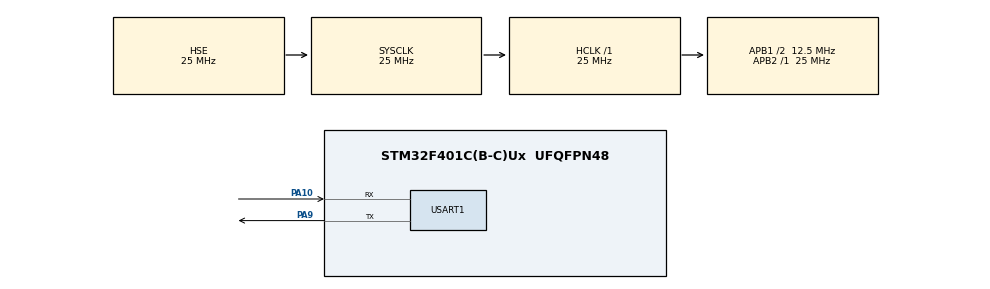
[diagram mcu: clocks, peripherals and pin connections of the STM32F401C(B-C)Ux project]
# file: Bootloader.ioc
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Mcu.Family=STM32F4
Mcu.Name=STM32F401C(B-C)Ux
Mcu.Package=UFQFPN48
NVIC.PriorityGroup=NVIC_PRIORITYGROUP_4
PA10.Mode=Asynchronous
PA10.Signal=USART1_RX
PA9.Mode=Asynchronous
PA9.Signal=USART1_TX
PH0\ -\ OSC_IN.Mode=HSE-External-Oscillator
PH0\ -\ OSC_IN.Signal=RCC_OSC_IN
PH1\ -\ OSC_OUT.Mode=HSE-External-Oscillator
PH1\ -\ OSC_OUT.Signal=RCC_OSC_OUT
ProjectManager.HeapSize=0x200
ProjectManager.StackSize=0x400
ProjectManager.TargetToolchain=STM32CubeIDE
RCC.48MHZClocksFreq_Value=26880000
RCC.AHBFreq_Value=25000000
RCC.APB1CLKDivider=RCC_HCLK_DIV2
RCC.APB1Freq_Value=12500000
RCC.APB1TimFreq_Value=25000000
RCC.APB2Freq_Value=25000000
RCC.APB2TimFreq_Value=25000000
RCC.CortexFreq_Value=25000000
RCC.HCLKFreq_Value=25000000
RCC.HSE_VALUE=25000000
RCC.HSI_VALUE=16000000
RCC.LSE_VALUE=32768
RCC.PLLM=25
RCC.PLLN=168
RCC.SYSCLKFreq_VALUE=25000000
RCC.SYSCLKSource=RCC_SYSCLKSOURCE_HSE
RCC.VCOOutputFreq_Value=107520000
USART1.VirtualMode=VM_ASYNC
VP_CRC_VS_CRC.Mode=CRC_Activate
board=custom

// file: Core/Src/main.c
/* USER CODE BEGIN Header */
/**
  ******************************************************************************
  * @file           : main.c
  * @brief          : Main program body
  ******************************************************************************
  * @attention
  *
  * Copyright (c) 2024 STMicroelectronics.
  * All rights reserved.
  *
  * This software is licensed under terms that can be found in the LICENSE file
  * in the root directory of this software component.
  * If no LICENSE file comes with this software, it is provided AS-IS.
  *
  ******************************************************************************
  */
/* USER CODE END Header */
#include "main.h"
#include "crc.h"
#include "usart.h"
#include "gpio.h"

/* USER CODE BEGIN Includes */
#include "bootloader.h"
/* USER CODE END Includes */

void SystemClock_Config(void);

int main(void)
{
  /* USER CODE BEGIN 1 */
	BL_Status Status = BL_NACK;
  /* USER CODE END 1 */

  /* MCU Configuration--------------------------------------------------------*/

  /* Reset of all peripherals, Initializes the Flash interface and the Systick. */
  HAL_Init();

  /* Configure the system clock */
  SystemClock_Config();

  /* Initialize all configured peripherals */
  MX_GPIO_Init();
  MX_CRC_Init();
  MX_USART1_UART_Init();

  /* Infinite loop */
  /* USER CODE BEGIN WHILE */
#if (BL_DEBUG_ENABLE == DEBUG_INFO_ENABLE)
	BL_Print_Message("Bootloader started. \r\n");
#endif

  while (1)
  {
    /* USER CODE END WHILE */
    /* USER CODE BEGIN 3 */
		Status = BL_UART_Fetch_Host_Command();

  }
  /* USER CODE END 3 */
}

void SystemClock_Config(void)
{
  RCC_OscInitTypeDef RCC_OscInitStruct = {0};
  RCC_ClkInitTypeDef RCC_ClkInitStruct = {0};

  /** Configure the main internal regulator output voltage
  */
  __HAL_RCC_PWR_CLK_ENABLE();
  __HAL_PWR_VOLTAGESCALING_CONFIG(PWR_REGULATOR_VOLTAGE_SCALE2);

  /** Initializes the RCC Oscillators according to the specified parameters
  * in the RCC_OscInitTypeDef structure.
  */
  RCC_OscInitStruct.OscillatorType = RCC_OSCILLATORTYPE_HSE;
  RCC_OscInitStruct.HSEState = RCC_HSE_ON;
  RCC_OscInitStruct.PLL.PLLState = RCC_PLL_NONE;
  if (HAL_RCC_OscConfig(&RCC_OscInitStruct) != HAL_OK)
  {
    Error_Handler();
  }

  /** Initializes the CPU, AHB and APB buses clocks
  */
  RCC_ClkInitStruct.ClockType = RCC_CLOCKTYPE_HCLK|RCC_CLOCKTYPE_SYSCLK
                              |RCC_CLOCKTYPE_PCLK1|RCC_CLOCKTYPE_PCLK2;
  RCC_ClkInitStruct.SYSCLKSource = RCC_SYSCLKSOURCE_HSE;
  RCC_ClkInitStruct.AHBCLKDivider = RCC_SYSCLK_DIV1;
  RCC_ClkInitStruct.APB1CLKDivider = RCC_HCLK_DIV2;
  RCC_ClkInitStruct.APB2CLKDivider = RCC_HCLK_DIV1;

  if (HAL_RCC_ClockConfig(&RCC_ClkInitStruct, FLASH_LATENCY_0) != HAL_OK)
  {
    Error_Handler();
  }
}

void Error_Handler(void)
{
  __disable_irq();
  while (1)
  {
  }
}
